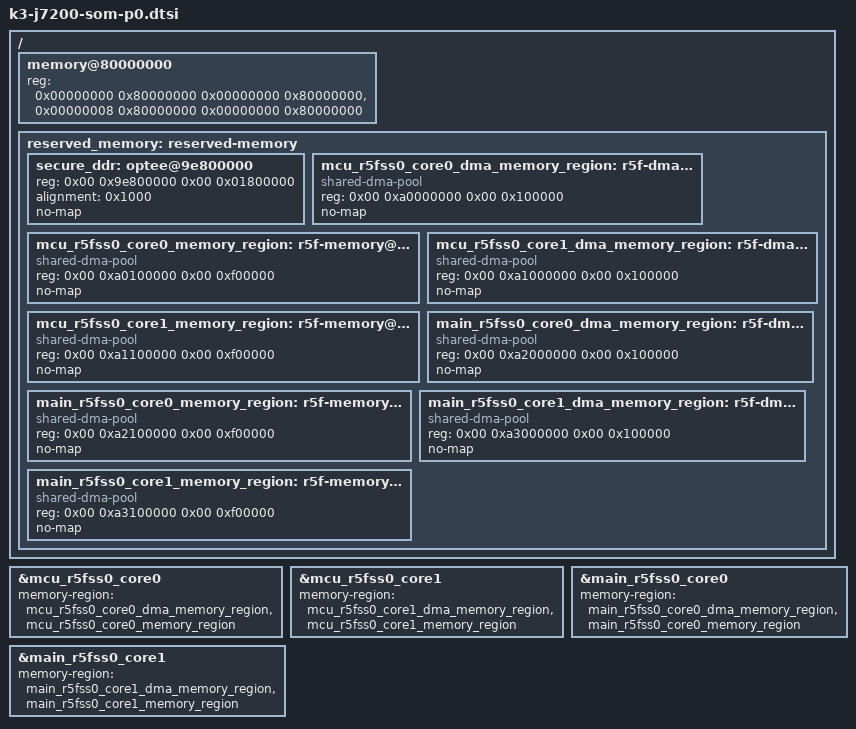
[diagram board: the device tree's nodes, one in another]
// SPDX-License-Identifier: GPL-2.0
/*
 * Copyright (C) 2020 Texas Instruments Incorporated - https://www.ti.com/
 */

/dts-v1/;

#include "k3-j7200.dtsi"

/ {
	memory@80000000 {
		device_type = "memory";
		/* 4G RAM */
		reg = <0x00000000 0x80000000 0x00000000 0x80000000>,
		      <0x00000008 0x80000000 0x00000000 0x80000000>;
	};

	reserved_memory: reserved-memory {
		#address-cells = <2>;
		#size-cells = <2>;
		ranges;

		secure_ddr: optee@9e800000 {
			reg = <0x00 0x9e800000 0x00 0x01800000>;
			alignment = <0x1000>;
			no-map;
		};

		mcu_r5fss0_core0_dma_memory_region: r5f-dma-memory@a0000000 {
			compatible = "shared-dma-pool";
			reg = <0x00 0xa0000000 0x00 0x100000>;
			no-map;
		};

		mcu_r5fss0_core0_memory_region: r5f-memory@a0100000 {
			compatible = "shared-dma-pool";
			reg = <0x00 0xa0100000 0x00 0xf00000>;
			no-map;
		};

		mcu_r5fss0_core1_dma_memory_region: r5f-dma-memory@a1000000 {
			compatible = "shared-dma-pool";
			reg = <0x00 0xa1000000 0x00 0x100000>;
			no-map;
		};

		mcu_r5fss0_core1_memory_region: r5f-memory@a1100000 {
			compatible = "shared-dma-pool";
			reg = <0x00 0xa1100000 0x00 0xf00000>;
			no-map;
		};

		main_r5fss0_core0_dma_memory_region: r5f-dma-memory@a2000000 {
			compatible = "shared-dma-pool";
			reg = <0x00 0xa2000000 0x00 0x100000>;
			no-map;
		};

		main_r5fss0_core0_memory_region: r5f-memory@a2100000 {
			compatible = "shared-dma-pool";
			reg = <0x00 0xa2100000 0x00 0xf00000>;
			no-map;
		};

		main_r5fss0_core1_dma_memory_region: r5f-dma-memory@a3000000 {
			compatible = "shared-dma-pool";
			reg = <0x00 0xa3000000 0x00 0x100000>;
			no-map;
		};

		main_r5fss0_core1_memory_region: r5f-memory@a3100000 {
			compatible = "shared-dma-pool";
			reg = <0x00 0xa3100000 0x00 0xf00000>;
			no-map;
		};
	};
};

&mcu_r5fss0_core0 {
	memory-region = <&mcu_r5fss0_core0_dma_memory_region>,
			<&mcu_r5fss0_core0_memory_region>;
};

&mcu_r5fss0_core1 {
	memory-region = <&mcu_r5fss0_core1_dma_memory_region>,
			<&mcu_r5fss0_core1_memory_region>;
};

&main_r5fss0_core0 {
	memory-region = <&main_r5fss0_core0_dma_memory_region>,
			<&main_r5fss0_core0_memory_region>;
};

&main_r5fss0_core1 {
	memory-region = <&main_r5fss0_core1_dma_memory_region>,
			<&main_r5fss0_core1_memory_region>;
};
